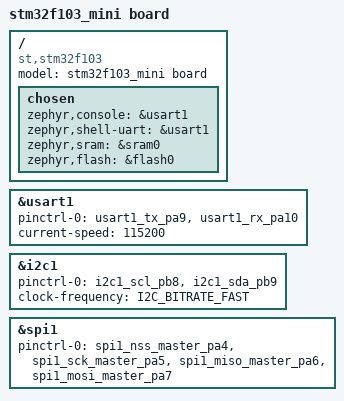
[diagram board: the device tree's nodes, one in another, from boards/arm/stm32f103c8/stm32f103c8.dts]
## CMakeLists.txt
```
cmake_minimum_required(VERSION 3.13.1)

# set(DTC_OVERLAY_FILE "${CMAKE_CURRENT_SOURCE_DIR}/custom.overlay")

find_package(Zephyr REQUIRED HINTS $ENV{ZEPHYR_BASE})
project(hello_world)

target_sources(
  app
  PRIVATE
  src/main.c
  src/usb.c
)
```

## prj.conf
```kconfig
# CONFIG_NO_OPTIMIZATIONS=y

CONFIG_REBOOT=y

CONFIG_I2C=y

CONFIG_SPI=y
CONFIG_SPI_0=y

CONFIG_LOG=y
CONFIG_LOG_MODE_IMMEDIATE=y
# CONFIG_LOG_BUFFER_SIZE=4096


# enable uart driver
CONFIG_SERIAL=y
# enable console
CONFIG_CONSOLE=y
CONFIG_UART_CONSOLE=y
# CONFIG_USB_UART_CONSOLE=y


# CONFIG_SHELL=y

CONFIG_USB=y
CONFIG_USB_DEVICE_STACK=y
CONFIG_USB_DRIVER_LOG_LEVEL_DBG=y
CONFIG_USB_DEVICE_LOG_LEVEL_DBG=y

CONFIG_USB_DEVICE_VID=0x1234
CONFIG_USB_DEVICE_PID=0x4321

# CONFIG_USB_DEVICE_HID=y
# CONFIG_ENABLE_HID_INT_OUT_EP=y
# CONFIG_USB_HID_LOG_LEVEL_DBG=y

CONFIG_USB_CDC_ACM=y
CONFIG_USB_COMPOSITE_DEVICE=y
CONFIG_USB_CDC_ACM_LOG_LEVEL_DBG=y
```

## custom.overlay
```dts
&usart1 {
    pinctrl-0 = <&usart3_tx_pb10 &usart3_rx_pb11>;
    current-speed = <115200>;
    status = "okay";
};

&usb {
    pinctrl-0 = <&usb_dm_pa11 &usb_dp_pa12>;
    status = "okay";
};
```

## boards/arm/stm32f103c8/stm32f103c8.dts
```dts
/*
 * Copyright (c) 2021 maxu
 *
 * SPDX-License-Identifier: Apache-2.0
 */

/dts-v1/;
#include <st/f1/stm32f103Xc.dtsi>
#include <st/f1/stm32f103r(c-d-e)tx-pinctrl.dtsi>

/ {
	model = "stm32f103_mini board";
	compatible = "st,stm32f103";

	chosen {
		zephyr,console = &usart1;
		zephyr,shell-uart = &usart1;
		zephyr,sram = &sram0;
		zephyr,flash = &flash0;
	};

};

&usart1 {
	pinctrl-0 = <&usart1_tx_pa9 &usart1_rx_pa10>;
	current-speed = <115200>;
	status = "okay";
};

&i2c1 {
	pinctrl-0 = <&i2c1_scl_pb8 &i2c1_sda_pb9>;
	status = "okay";
	clock-frequency = <I2C_BITRATE_FAST>;
};

&spi1 {
	pinctrl-0 = <&spi1_nss_master_pa4 &spi1_sck_master_pa5
		     &spi1_miso_master_pa6 &spi1_mosi_master_pa7>;
	status = "okay";
};
```

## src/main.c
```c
#include <zephyr.h>
#include <sys/printk.h>

void main(void)
{
    printk("Hello World! %s\n", CONFIG_BOARD);
}
```
